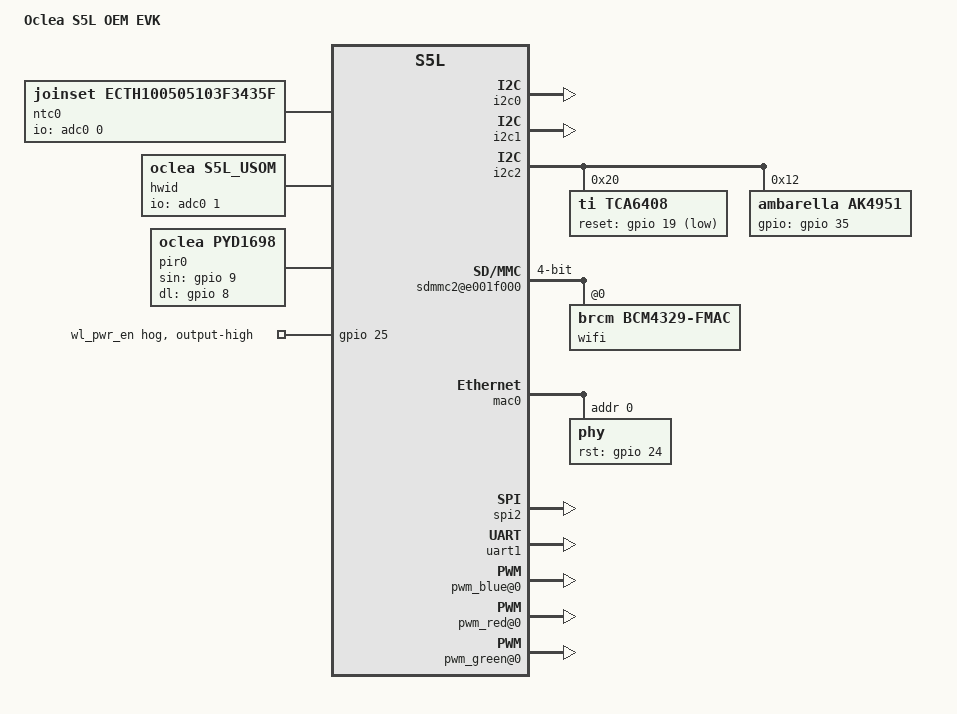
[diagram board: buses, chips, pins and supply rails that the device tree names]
/dts-v1/;
/include/ "ambarella-s5l.dtsi"
/include/ "s5l_oclea_cma.dtsi"
/include/ "s5l_oclea_private.dtsi"
/ {
 model = "Oclea S5L OEM EVK";
 model-revision = "Oclea S5L Janus";
 compatible = "ambarella,hal", "ambarella,s5l";
 oclea-vin-version = <2>;
 chosen {
  bootargs = "console=ttyS0 noinitrd root=##ROOT_DEVICE## rw rootfstype=ext4 rootwait init=/sbin/init";
 };
 apb@e8000000 {
  pinctrl: pinctrl@e8009000 {
   usb_host0_pins: uhc0@0 {
    reg = <0>;
    amb,pinmux-ids = <0x1001>;
   };
  };
  ntc0: ntc0 {
   compatible = "joinset,ecth100505103f3435f";
   pullup-uv = <3300000>;
   pullup-ohm = <10000>;
   pulldown-ohm = <0>;
   io-channels = <&adc0 0>;
   alias-name = "main-ntc";
   #thermal-sensor-cells = <0>;
  };
  hwid {
   compatible = "oclea,s5l_uSOM";
   pullup-mv = <3300>;
   io-channels = <&adc0 1>;
   alias-name = "hwid";
  };
  adc0: adc@e801d000 {
   amb,channels-used = <0x0a>;
   #io-channel-cells = <1>;
  };
  pir0: pir0 {
   compatible = "oclea,pyd1698";
   sin-gpio = <&gpio 9 0x0>;
   dl-gpio = <&gpio 8 0x0>;
   dev-name = "iio:pir0";
  };
  i2c0: i2c@e8003000 {
   status = "ok";
  };
  i2c1: i2c@e8001000 {
   status = "ok";
  };
  i2c2: i2c@e8007000 {
   status = "ok";
   tca6408: tca6408@20 {
    compatible = "ti,tca6408";
    reg = <0x20>;
    gpio-controller;
    interrupt-parent = <&gpio>;
    interrupt-controller;
    #gpio-cells = <1>;
    reset-gpios = <&gpio 19 1>;
    port-0-0 {
     gpios = <0 0>;
     output-low;
    };
    port-0-1 {
     gpios = <1 0>;
     output-low;
    };
    port-0-2 {
     gpios = <2 0>;
     output-low;
    };
    port-0-3 {
     gpios = <3 0>;
     output-low;
    };
    port-0-4 {
     gpios = <4 0>;
     output-low;
    };
    port-0-5 {
     gpios = <5 0>;
     output-low;
    };
    port-0-6 {
     gpios = <6 0>;
     output-low;
    };
    port-0-7 {
     gpios = <7 0>;
     output-low;
    };
   };
   ak4951: codec@12 {
    compatible = "ambarella,ak4951";
    #sound-dai-cells = <0>;
    reg = <0x12>;
    gpios = <&gpio 35 0x0>;
    amb,dmic;
   };
  };
  ir@e8006000 {
   status = "disabled";
  };
 };
 ahb@e0000000 {
  sdmmc0@e0002000 {
   amb,emmc-boot;
   amb,sd-force-1_8v;
   amb,fixed-cd = <1>;
  };
  sdmmc2@e001f000 {
   status = "ok";
   pinctrl-0 = <&sdmmc2_pins_4bit &sdmmc2_cd_pin>;
   bus-width = <4>;
   no-1-8-v;
   amb,fixed-cd = <1>;
   amb,fixed-wp = <0>;
   no-mmc;
   no-sd;
   pwr-gpios = <&gpio 11 0x1>;
   wifi@0 {
    compatible = "brcm,bcm4329-fmac";
    reg = <0>;
   };
  };
  mac0: ethernet@e000e000 {
   amb,tx-clk-invert;
   amb,override-phy-type;
   phy@0 {
    reg = <0>;
    rst-gpios = <&gpio 24 0x0>;
    max-speed = <100>;
    rst-gpio-delay = <100>;
    teknique,rtl8211f-active-led-id-mask = <0x5>;
   };
  };
  nand0: nand@e0001000 {
   status = "disabled";
  };
  spi0: spi@e0020000 {
   status = "disabled";
  };
  spi2: spi@e0022000 {
   status = "ok";
   cs-gpios = <&gpio 43 0>, <&gpio 44 0>;
  };
  uart1: uart@e0032000 {
      status = "ok";
  };
  hdmi@e0013000 {
   amb,i2c-adapter = <1>;
   pinctrl-names = "default";
   pinctrl-0 = <&hdmi_pin>;
  };
 };
 rct@ec170000 {
  usbphy: usbphy@ec170050 {
   amb,ocp-polarity = <1>;
   pinctrl-names = "default";
   pinctrl-0 = <&usb_host0_pins>;
  };
 };
 bogus_bus {
  pwm_blue@0 {
   compatible = "pwm-backlight";
   reg = <0>;
   pwms = <&pwm 0 40000 0>;
   pinctrl-names = "default";
   pinctrl-0 = <&pwm0_pins_b>;
   brightness-levels =
    <0 1 2 3 4 5 6 7 8 9 10 11 12 13 14 15
    16 17 18 19 20 21 22 23 24 25 26 27 28 29 30 31
    32 33 34 35 36 37 38 39 40 41 42 43 44 45 46 47
    48 49 50 51 52 53 54 55 56 57 58 59 60 61 62 63
    64 65 66 67 68 69 70 71 72 73 74 75 76 77 78 79
    80 81 82 83 84 85 86 87 88 89 90 91 92 93 94 95
    96 97 98 99 100 101 102 103 104 105 106 107 108 109 110 111
    112 113 114 115 116 117 118 119 120 121 122 123 124 125 126 127
    128 129 130 131 132 133 134 135 136 137 138 139 140 141 142 143
    144 145 146 147 148 149 150 151 152 153 154 155 156 157 158 159
    160 161 162 163 164 165 166 167 168 169 170 171 172 173 174 175
    176 177 178 179 180 181 182 183 184 185 186 187 188 189 190 191
    192 193 194 195 196 197 198 199 200 201 202 203 204 205 206 207
    208 209 210 211 212 213 214 215 216 217 218 219 220 221 222 223
    224 225 226 227 228 229 230 231 232 233 234 235 236 237 238 239
    240 241 242 243 244 245 246 247 248 249 250 251 252 253 254 255>;
   default-brightness-level = <0>;
  };
  pwm_red@0 {
   compatible = "pwm-backlight";
   reg = <1>;
   pwms = <&pwm 1 40000 0>;
   pinctrl-names = "default";
   pinctrl-0 = <&pwm1_pins_c>;
   brightness-levels =
    <0 1 2 3 4 5 6 7 8 9 10 11 12 13 14 15
    16 17 18 19 20 21 22 23 24 25 26 27 28 29 30 31
    32 33 34 35 36 37 38 39 40 41 42 43 44 45 46 47
    48 49 50 51 52 53 54 55 56 57 58 59 60 61 62 63
    64 65 66 67 68 69 70 71 72 73 74 75 76 77 78 79
    80 81 82 83 84 85 86 87 88 89 90 91 92 93 94 95
    96 97 98 99 100 101 102 103 104 105 106 107 108 109 110 111
    112 113 114 115 116 117 118 119 120 121 122 123 124 125 126 127
    128 129 130 131 132 133 134 135 136 137 138 139 140 141 142 143
    144 145 146 147 148 149 150 151 152 153 154 155 156 157 158 159
    160 161 162 163 164 165 166 167 168 169 170 171 172 173 174 175
    176 177 178 179 180 181 182 183 184 185 186 187 188 189 190 191
    192 193 194 195 196 197 198 199 200 201 202 203 204 205 206 207
    208 209 210 211 212 213 214 215 216 217 218 219 220 221 222 223
    224 225 226 227 228 229 230 231 232 233 234 235 236 237 238 239
    240 241 242 243 244 245 246 247 248 249 250 251 252 253 254 255>;
   default-brightness-level = <0>;
  };
  pwm_green@0 {
   compatible = "pwm-backlight";
   reg = <2>;
   pwms = <&pwm 2 40000 0>;
   pinctrl-names = "default";
   pinctrl-0 = <&pwm2_pins_c>;
   brightness-levels =
    <0 1 2 3 4 5 6 7 8 9 10 11 12 13 14 15
    16 17 18 19 20 21 22 23 24 25 26 27 28 29 30 31
    32 33 34 35 36 37 38 39 40 41 42 43 44 45 46 47
    48 49 50 51 52 53 54 55 56 57 58 59 60 61 62 63
    64 65 66 67 68 69 70 71 72 73 74 75 76 77 78 79
    80 81 82 83 84 85 86 87 88 89 90 91 92 93 94 95
    96 97 98 99 100 101 102 103 104 105 106 107 108 109 110 111
    112 113 114 115 116 117 118 119 120 121 122 123 124 125 126 127
    128 129 130 131 132 133 134 135 136 137 138 139 140 141 142 143
    144 145 146 147 148 149 150 151 152 153 154 155 156 157 158 159
    160 161 162 163 164 165 166 167 168 169 170 171 172 173 174 175
    176 177 178 179 180 181 182 183 184 185 186 187 188 189 190 191
    192 193 194 195 196 197 198 199 200 201 202 203 204 205 206 207
    208 209 210 211 212 213 214 215 216 217 218 219 220 221 222 223
    224 225 226 227 228 229 230 231 232 233 234 235 236 237 238 239
    240 241 242 243 244 245 246 247 248 249 250 251 252 253 254 255>;
   default-brightness-level = <0>;
  };
  ir_led@0 {
   compatible = "pwm-backlight";
   reg = <3>;
   pwms = <&pwm 3 40000 0>;
   pinctrl-names = "default";
   pinctrl-0 = <&pwm3_pins_c>;
   brightness-levels =
    <0 1 2 3 4 5 6 7 8 9 10 11 12 13 14 15
    16 17 18 19 20 21 22 23 24 25 26 27 28 29 30 31
    32 33 34 35 36 37 38 39 40 41 42 43 44 45 46 47
    48 49 50 51 52 53 54 55 56 57 58 59 60 61 62 63
    64 65 66 67 68 69 70 71 72 73 74 75 76 77 78 79
    80 81 82 83 84 85 86 87 88 89 90 91 92 93 94 95
    96 97 98 99 100 101 102 103 104 105 106 107 108 109 110 111
    112 113 114 115 116 117 118 119 120 121 122 123 124 125 126 127
    128 129 130 131 132 133 134 135 136 137 138 139 140 141 142 143
    144 145 146 147 148 149 150 151 152 153 154 155 156 157 158 159
    160 161 162 163 164 165 166 167 168 169 170 171 172 173 174 175
    176 177 178 179 180 181 182 183 184 185 186 187 188 189 190 191
    192 193 194 195 196 197 198 199 200 201 202 203 204 205 206 207
    208 209 210 211 212 213 214 215 216 217 218 219 220 221 222 223
    224 225 226 227 228 229 230 231 232 233 234 235 236 237 238 239
    240 241 242 243 244 245 246 247 248 249 250 251 252 253 254 255>;
   default-brightness-level = <0>;
  };
 };
 iav {
  vinc0 {
  };
  vinc1 {
  };
  hwtimer {
   compatible = "ambarella,hwtimer";
   interrupts = <0 3 0x1>;
   interrupt-names = "hwtimer";
  };
 };
 sound {
  compatible = "ambarella,audio-board";
  simple-audio-card,name = "ak4951 @ HAL";
  simple-audio-card,mclk-fs = <256>;
  simple-audio-card,widgets =
   "Speaker", "Speaker",
   "Microphone", "Mic Internal";
  simple-audio-card,routing =
   "DMICLIN", "Mic Internal",
   "DMICRIN", "Mic Internal",
   "DMICL", "DMICLIN",
   "DMICR", "DMICRIN",
   "MIC MUX", "DMICL",
   "MIC MUX", "DMICR",
   "PFSDO MUX", "MIC MUX",
   "SDTO", "PFSDO MUX",
   "PFDAC MUX", "SDTI",
   "DAC", "PFDAC MUX",
   "SPKLO Mixer", "DAC",
   "SPK Amp", "SPKLO Mixer",
   "SPKLO MUX", "SPK Amp",
   "SPKLO", "SPKLO MUX",
   "Speaker", "SPKLO";
  simple-audio-card,dai-link@0 {
   format = "i2s";
   cpu {
    sound-dai = <&i2s0>;
   };
   codec {
    sound-dai = <&ak4951>;
   };
  };
 };
 clocks {
  gclk_vo: gclk-vo {
   assigned-clock-rates = <0> ;
  };
 };
 thermal-zones {
  soc_thermal: soc-thermal {
   polling-delay-passive = <250>;
   polling-delay = <1000>;
   thermal-sensors = <&ntc0>;
   trips {
    soc_alert: soc-alert {
     temperature = <80000>;
     hysteresis = <1000>;
     type = "passive";
    };
    soc_crit: soc-crit {
     temperature = <85000>;
     hysteresis = <1000>;
     type = "critical";
    };
   };
  };
 };
};
&gpio {
 gpio-line-names =
  "", "", "", "", "", "", "bt-en", "",
  "", "", "", "wl-reg-on", "", "", "", "",
  "", "", "", "", "", "", "", "",
  "", "wl-pwr-en", "", "", "", "", "", "",
  "", "", "", "", "", "", "", "",
  "", "", "", "", "", "", "", "",
  "", "", "", "", "", "", "", "",
  "", "", "", "", "", "", "", "",
  "", "", "", "", "", "", "", "",
  "", "", "", "", "", "", "", "",
  "", "", "", "", "", "", "", "",
  "", "", "", "", "", "", "", "",
  "", "", "", "", "", "", "", "",
  "", "", "", "", "", "", "", "",
  "", "", "", "", "", "", "", "",
  "", "", "", "", "", "", "", "";
 wl_pwr_en {
  gpio-hog;
  gpios = <25 0>;
  output-high;
 };
};
